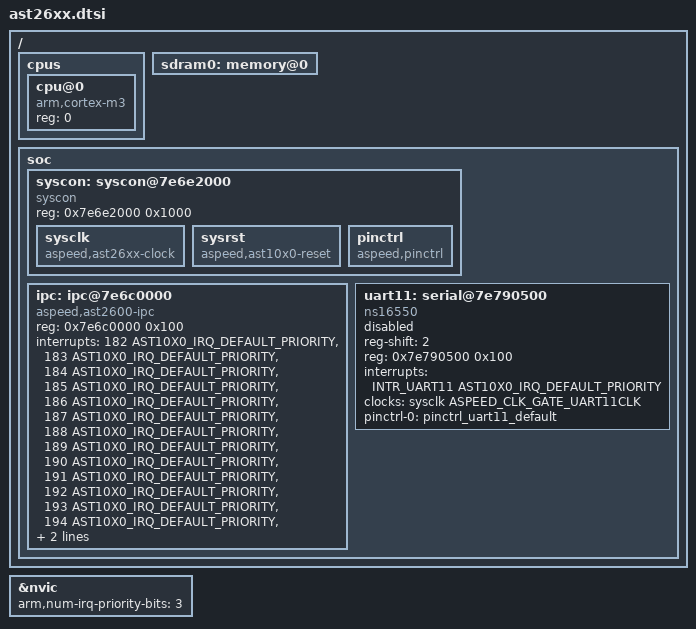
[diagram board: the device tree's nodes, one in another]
/*
 * SPDX-License-Identifier: Apache-2.0
 *
 * Copyright (c) 2021 ASPEED Technology Inc.
 */

#include <arm/armv7-m.dtsi>
#include <mem.h>
#include <aspeed/ast10x0-irq.h>
#include <zephyr/dt-bindings/clock/ast26xx_clock.h>
#include <zephyr/dt-bindings/reset/ast26xx_reset.h>
#include <zephyr/dt-bindings/pinctrl/ast26xx-pinctrl-groups.h>

/ {
	cpus {
		#address-cells = <1>;
		#size-cells = <0>;

		cpu@0 {
			device_type = "cpu";
			compatible = "arm,cortex-m3";
			reg = <0>;
		};
	};

	sdram0: memory@0 {
		device_type = "memory";
	};

	soc {
		syscon: syscon@7e6e2000 {
			compatible = "syscon";
			reg = <0x7e6e2000 0x1000>;
			sysclk: sysclk {
				compatible = "aspeed,ast26xx-clock";
				#clock-cells = <1>;
			};

			sysrst: sysrst {
				compatible = "aspeed,ast10x0-reset";
				#reset-cells = <1>;
			};

			pinctrl: pinctrl {
				compatible = "aspeed,pinctrl";
			};
		};

		ipc: ipc@7e6c0000 {
			compatible = "aspeed,ast2600-ipc";
			reg = <0x7e6c0000 0x100>;
			interrupts = <182 AST10X0_IRQ_DEFAULT_PRIORITY>,
				     <183 AST10X0_IRQ_DEFAULT_PRIORITY>,
				     <184 AST10X0_IRQ_DEFAULT_PRIORITY>,
				     <185 AST10X0_IRQ_DEFAULT_PRIORITY>,
				     <186 AST10X0_IRQ_DEFAULT_PRIORITY>,
				     <187 AST10X0_IRQ_DEFAULT_PRIORITY>,
				     <188 AST10X0_IRQ_DEFAULT_PRIORITY>,
				     <189 AST10X0_IRQ_DEFAULT_PRIORITY>,
				     <190 AST10X0_IRQ_DEFAULT_PRIORITY>,
				     <191 AST10X0_IRQ_DEFAULT_PRIORITY>,
				     <192 AST10X0_IRQ_DEFAULT_PRIORITY>,
				     <193 AST10X0_IRQ_DEFAULT_PRIORITY>,
				     <194 AST10X0_IRQ_DEFAULT_PRIORITY>,
				     <195 AST10X0_IRQ_DEFAULT_PRIORITY>,
				     <196 AST10X0_IRQ_DEFAULT_PRIORITY>;
		};

		uart11: serial@7e790500 {
			compatible = "ns16550";
			reg-shift = <2>;
			reg = <0x7e790500 0x100>;
			interrupts = <INTR_UART11 AST10X0_IRQ_DEFAULT_PRIORITY>;
			clocks = <&sysclk ASPEED_CLK_GATE_UART11CLK>;
			status = "disabled";
			pinctrl-0 = <pinctrl_uart11_default>;
			pinctrl-names = "default";
		};
	};
};

&nvic {
	arm,num-irq-priority-bits = <3>;
};

#include "ast10x0-pinctrl.dtsi"
